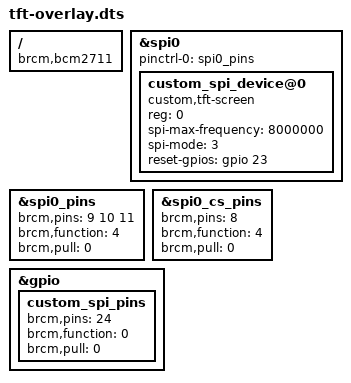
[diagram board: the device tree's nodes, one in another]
/dts-v1/;
/plugin/;

/ {
    compatible = "brcm,bcm2711";
    
    fragment@0 {
        target = <&spi0>;
        __overlay__ {
            #address-cells = <1>;
            #size-cells = <0>;
            status = "okay";
            
            /* SPI controller configuration */
            pinctrl-names = "default";
            pinctrl-0 = <&spi0_pins>;
            
            /* Custom device on SPI0 */
            custom_spi_device@0 {
                compatible = "custom,tft-screen";
                reg = <0>;  /* Chip select 0, which is GPIO 8 */
                spi-max-frequency = <8000000>;  /* 8 MHz clock */
		        spi-mode = <3>;
                status = "okay";
                
                /* Additional properties for your driver */
                reset-gpios = <&gpio 23 0>;  /* GPIO 23, active HIGH */
            };
        };
    };
    
    fragment@1 {
        target = <&spi0_pins>;
        __overlay__ {
            brcm,pins = <9 10 11>;  /* MISO, MOSI, SCLK */
            brcm,function = <4>;    /* Alt function 0 for SPI */
            brcm,pull = <0>;        /* No pull resistors */
        };
    };
    
    fragment@2 {
        target = <&spi0_cs_pins>;
        __overlay__ {
            brcm,pins = <8>;        /* Chip Enable 0 pin which is GPIO8 */
            brcm,function = <4>;    /* Alt function 0 for SPI */
            brcm,pull = <0>;        /* No pull resistor */
        };
    };
    
    fragment@3 {
        target = <&gpio>;
        __overlay__ {
            custom_spi_pins: custom_spi_pins {
                brcm,pins = <24>;    /* Additional GPIO pins for reset/interrupt */
                brcm,function = <0>;    /* GPIO input/output */
                brcm,pull = <0>;        /* No pull resistors */
            };
        };
    };
    
    __overrides__ {
        /* Override parameters that can be set during overlay loading */
        spi_freq = <&custom_spi_device>,"spi-max-frequency:0";
        cs_pin = <&custom_spi_device>,"reg:0";
        reset_pin = <&custom_spi_device>,"reset-gpios:4";
        compatible = <&custom_spi_device>,"compatible";
    };
};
